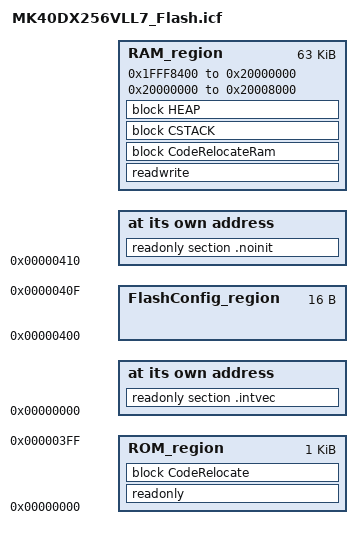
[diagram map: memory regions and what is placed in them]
/*###ICF### Section handled by ICF editor, don't touch! ****/
/*-Editor annotation file-*/
/* IcfEditorFile="$TOOLKIT_DIR$\config\ide\IcfEditor\cortex_v1_0.xml" */
/*-Memory Regions-*/
define symbol __ICFEDIT_region_ROM_start__ = 0x0;
define symbol __ICFEDIT_region_ROM_end__   = __ICFEDIT_region_ROM_start__ + 0x40000;     //********
define symbol __ICFEDIT_region_RAM_end__   = 0x20000000;
define symbol __ICFEDIT_region_RAM_start__ = __ICFEDIT_region_RAM_end__ - 0x8000 + 0x400; //********
/*-Specials-*/
define symbol __ICFEDIT_intvec_start__ = __ICFEDIT_region_ROM_start__;

/*-Sizes-*/
define symbol __ICFEDIT_size_cstack__ = 0x2000; //********
define symbol __ICFEDIT_size_heap__   = 0x2000; //********
/**** End of ICF editor section. ###ICF###*/

define symbol __region_RAM2_start__        = 0x20000000;
define symbol __region_RAM2_end__          = __region_RAM2_start__ + 0x8000;//********
//define symbol __region_FlexNVM_start__     = 0x10000000;//********
//define symbol __region_FlexNVM_end__       = __region_FlexNVM_start__ + 0x8000;//********

define exported symbol __VECTOR_TABLE      = 0x00000000;
define exported symbol __VECTOR_RAM        = __ICFEDIT_region_RAM_start__ - 0x400;

define exported symbol __BOOT_STACK_ADDRESS = __region_RAM2_end__ - 8;

define symbol __code_start__ = 0x00000410;//********

define symbol FlashConfig_start__= 0x00000400;
define symbol FlashConfig_end__  = 0x0000040f;

define memory mem with size = 4G;
//define region ROM_region   = mem:[from __ICFEDIT_region_ROM_start__   to __ICFEDIT_region_ROM_end__];// | mem:[from __region_FlexNVM_start__ to __region_FlexNVM_end__];//********
define region ROM_region   = mem:[from __ICFEDIT_region_ROM_start__ to (FlashConfig_start__ - 1)] | [from (FlashConfig_end__+1)  to __ICFEDIT_region_ROM_end__];
define region RAM_region   = mem:[from __ICFEDIT_region_RAM_start__   to __ICFEDIT_region_RAM_end__] | mem:[from __region_RAM2_start__ to __region_RAM2_end__];

define block CSTACK    with alignment = 8, size = __ICFEDIT_size_cstack__   { };
define block HEAP      with alignment = 8, size = __ICFEDIT_size_heap__     { };

define region FlashConfig_region = mem:[from FlashConfig_start__ to FlashConfig_end__];

initialize by copy  { readwrite };
do not initialize  { section .noinit };

define block CodeRelocate { section .textrw_init };
define block CodeRelocateRam { section .textrw };
place at address mem:__ICFEDIT_intvec_start__ { readonly section .intvec };
place at address mem:__code_start__ { readonly section .noinit };

place in ROM_region   { readonly, block CodeRelocate};

place in RAM_region   { readwrite, block CodeRelocateRam,
                        block CSTACK, block HEAP };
